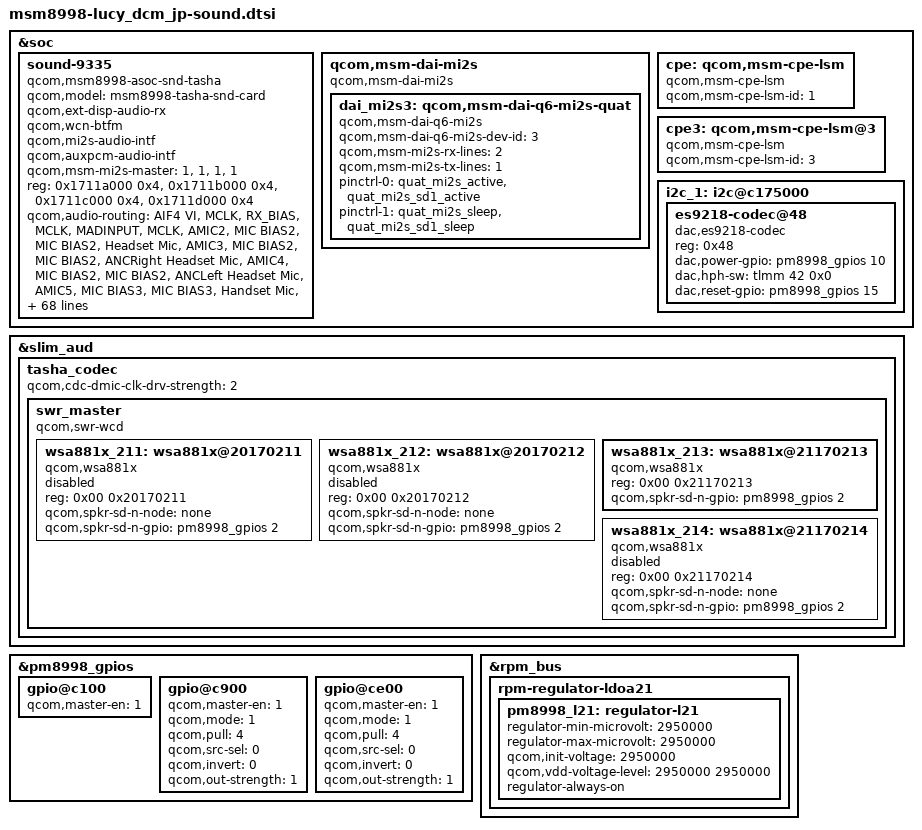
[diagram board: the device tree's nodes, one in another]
/* Copyright (c) 2016, The Linux Foundation. All rights reserved.
 *
 * This program is free software; you can redistribute it and/or modify
 * it under the terms of the GNU General Public License version 2 and
 * only version 2 as published by the Free Software Foundation.
 *
 * This program is distributed in the hope that it will be useful,
 * but WITHOUT ANY WARRANTY; without even the implied warranty of
 * MERCHANTABILITY or FITNESS FOR A PARTICULAR PURPOSE.  See the
 * GNU General Public License for more details.
 */

&soc {
	/delete-node/ sound-tavil;
	/delete-node/ msm_cdc_pinctrl@75;
	/delete-node/ qcom,wcd-dsp-mgr;

	sound-9335 {
		compatible = "qcom,msm8998-asoc-snd-tasha";
		qcom,model = "msm8998-tasha-snd-card";
		qcom,ext-disp-audio-rx;
		qcom,wcn-btfm;
		qcom,mi2s-audio-intf;
		qcom,auxpcm-audio-intf;
		qcom,msm-mi2s-master = <1>, <1>, <1>, <1>;

		reg = <0x1711a000 0x4>,
		      <0x1711b000 0x4>,
		      <0x1711c000 0x4>,
		      <0x1711d000 0x4>;
		reg-names = "lpaif_pri_mode_muxsel",
			    "lpaif_sec_mode_muxsel",
			    "lpaif_tert_mode_muxsel",
			    "lpaif_quat_mode_muxsel";

		qcom,audio-routing =
			"AIF4 VI", "MCLK",
			"RX_BIAS", "MCLK",
			"MADINPUT", "MCLK",
			"AMIC2", "MIC BIAS2",
			"MIC BIAS2", "Headset Mic",
			"AMIC3", "MIC BIAS2",
			"MIC BIAS2", "ANCRight Headset Mic",
			"AMIC4", "MIC BIAS2",
			"MIC BIAS2", "ANCLeft Headset Mic",
			"AMIC5", "MIC BIAS3",
			"MIC BIAS3", "Handset Mic",
			"AMIC6", "MIC BIAS4",
			"MIC BIAS4", "Analog Mic6",
			"DMIC0", "MIC BIAS1",
			"MIC BIAS1", "Digital Mic0",
			"DMIC1", "MIC BIAS1",
			"MIC BIAS1", "Digital Mic1",
			"DMIC2", "MIC BIAS3",
			"MIC BIAS3", "Digital Mic2",
			"DMIC3", "MIC BIAS3",
			"MIC BIAS3", "Digital Mic3",
			"DMIC4", "MIC BIAS4",
			"MIC BIAS4", "Digital Mic4",
			"DMIC5", "MIC BIAS4",
			"MIC BIAS4", "Digital Mic5",
			"SpkrLeft IN", "SPK1 OUT";

		qcom,msm-mbhc-hphl-swh = <1>;
		qcom,msm-mbhc-gnd-swh = <0>;
		qcom,mbhc-audio-jack-type = "4-pole-jack";
		/delete-property/ qcom,us-euro-gpios;
		lge,msm-mbhc-extn-cable = <0>;

		qcom,tasha-mclk-clk-freq = <9600000>;
		asoc-platform = <&pcm0>, <&pcm1>, <&pcm2>, <&voip>, <&voice>,
				<&loopback>, <&compress>, <&hostless>,
				<&afe>, <&lsm>, <&routing>, <&cpe>, <&compr>,
				<&pcm_noirq>, <&cpe3>;
		asoc-platform-names = "msm-pcm-dsp.0", "msm-pcm-dsp.1",
				"msm-pcm-dsp.2", "msm-voip-dsp",
				"msm-pcm-voice", "msm-pcm-loopback",
				"msm-compress-dsp", "msm-pcm-hostless",
				"msm-pcm-afe", "msm-lsm-client",
				"msm-pcm-routing", "msm-cpe-lsm",
				"msm-compr-dsp", "msm-pcm-dsp-noirq",
				"msm-cpe-lsm.3";
		asoc-cpu = <&dai_hdmi>, <&dai_dp>,
				<&dai_mi2s0>, <&dai_mi2s1>,
				<&dai_mi2s2>, <&dai_mi2s3>,
				<&dai_pri_auxpcm>, <&dai_sec_auxpcm>,
				<&dai_tert_auxpcm>, <&dai_quat_auxpcm>,
				<&sb_0_rx>, <&sb_0_tx>, <&sb_1_rx>, <&sb_1_tx>,
				<&sb_2_rx>, <&sb_2_tx>, <&sb_3_rx>, <&sb_3_tx>,
				<&sb_4_rx>, <&sb_4_tx>, <&sb_5_tx>,
				<&afe_pcm_rx>, <&afe_pcm_tx>, <&afe_proxy_rx>,
				<&afe_proxy_tx>, <&incall_record_rx>,
				<&incall_record_tx>, <&incall_music_rx>,
				<&incall_music_2_rx>, <&sb_5_rx>, <&sb_6_rx>,
				<&sb_7_rx>, <&sb_7_tx>, <&sb_8_tx>,
				<&usb_audio_rx>, <&usb_audio_tx>,
				<&dai_pri_tdm_rx_0>, <&dai_pri_tdm_tx_0>,
				<&dai_sec_tdm_rx_0>, <&dai_sec_tdm_tx_0>,
				<&dai_tert_tdm_rx_0>, <&dai_tert_tdm_tx_0>,
				<&dai_quat_tdm_rx_0>, <&dai_quat_tdm_tx_0>;
		asoc-cpu-names = "msm-dai-q6-hdmi.8", "msm-dai-q6-dp.24608",
				"msm-dai-q6-mi2s.0", "msm-dai-q6-mi2s.1",
				"msm-dai-q6-mi2s.2", "msm-dai-q6-mi2s.3",
				"msm-dai-q6-auxpcm.1", "msm-dai-q6-auxpcm.2",
				"msm-dai-q6-auxpcm.3", "msm-dai-q6-auxpcm.4",
				"msm-dai-q6-dev.16384", "msm-dai-q6-dev.16385",
				"msm-dai-q6-dev.16386", "msm-dai-q6-dev.16387",
				"msm-dai-q6-dev.16388", "msm-dai-q6-dev.16389",
				"msm-dai-q6-dev.16390", "msm-dai-q6-dev.16391",
				"msm-dai-q6-dev.16392", "msm-dai-q6-dev.16393",
				"msm-dai-q6-dev.16395", "msm-dai-q6-dev.224",
				"msm-dai-q6-dev.225", "msm-dai-q6-dev.241",
				"msm-dai-q6-dev.240", "msm-dai-q6-dev.32771",
				"msm-dai-q6-dev.32772", "msm-dai-q6-dev.32773",
				"msm-dai-q6-dev.32770", "msm-dai-q6-dev.16394",
				"msm-dai-q6-dev.16396", "msm-dai-q6-dev.16398",
				"msm-dai-q6-dev.16399", "msm-dai-q6-dev.16401",
				"msm-dai-q6-dev.28672", "msm-dai-q6-dev.28673",
				"msm-dai-q6-tdm.36864", "msm-dai-q6-tdm.36865",
				"msm-dai-q6-tdm.36880", "msm-dai-q6-tdm.36881",
				"msm-dai-q6-tdm.36896", "msm-dai-q6-tdm.36897",
				"msm-dai-q6-tdm.36912", "msm-dai-q6-tdm.36913";
		asoc-codec = <&stub_codec>, <&ext_disp_audio_codec>;
		asoc-codec-names = "msm-stub-codec.1",
				   "msm-ext-disp-audio-codec-rx";
		qcom,wsa-max-devs = <1>;
		qcom,wsa-devs = <&wsa881x_213>;
		qcom,wsa-aux-dev-prefix = "SpkrLeft";
		qcom,wcn-btfm;
	};

	qcom,msm-dai-mi2s {
		compatible = "qcom,msm-dai-mi2s";
		dai_mi2s3: qcom,msm-dai-q6-mi2s-quat {
			compatible = "qcom,msm-dai-q6-mi2s";
			qcom,msm-dai-q6-mi2s-dev-id = <3>;
			qcom,msm-mi2s-rx-lines = <2>; /* SD1 used as output */
			qcom,msm-mi2s-tx-lines = <1>; /* SD0 used as input */
			pinctrl-names = "default", "idle";
			pinctrl-0 = <&quat_mi2s_active &quat_mi2s_sd1_active>;
			pinctrl-1 = <&quat_mi2s_sleep &quat_mi2s_sd1_sleep>;
		};
	};

	cpe: qcom,msm-cpe-lsm {
		compatible = "qcom,msm-cpe-lsm";
		qcom,msm-cpe-lsm-id = <1>;
	};

	cpe3: qcom,msm-cpe-lsm@3 {
		compatible = "qcom,msm-cpe-lsm";
		qcom,msm-cpe-lsm-id = <3>;
	};

	i2c_1: i2c@c175000 { /* BLSP1 QUP1 */
		status = "okay";

		es9218-codec@48 {
			compatible = "dac,es9218-codec";
			status = "ok";
			reg = <0x48>;
			dac,power-gpio = <&pm8998_gpios 10 0x0>;
			dac,hph-sw = <&tlmm 42 0x0>;
			dac,reset-gpio = <&pm8998_gpios 15 0x0>;
		};
	};

};

&slim_aud {
	/delete-node/ tavil_codec;

	tasha_codec {
		qcom,cdc-dmic-clk-drv-strength = <2>;
		swr_master {
			compatible = "qcom,swr-wcd";
			#address-cells = <2>;
			#size-cells = <0>;
			wsa881x_211: wsa881x@20170211 {
				compatible = "qcom,wsa881x";
				reg = <0x00 0x20170211>;
				qcom,spkr-sd-n-node = "none";
				qcom,spkr-sd-n-gpio = <&pm8998_gpios 2 0>;
				status = "disabled";
			};
			wsa881x_212: wsa881x@20170212 {
				compatible = "qcom,wsa881x";
				reg = <0x00 0x20170212>;
				qcom,spkr-sd-n-node = "none";
				qcom,spkr-sd-n-gpio = <&pm8998_gpios 2 0>;
				status = "disabled";
			};
			wsa881x_213: wsa881x@21170213 {
				compatible = "qcom,wsa881x";
				reg = <0x00 0x21170213>;
				/delete-property/ qcom,spkr-sd-n-node;
				qcom,spkr-sd-n-gpio = <&pm8998_gpios 2 0>;
				status = "ok";
			};
			wsa881x_214: wsa881x@21170214 {
				compatible = "qcom,wsa881x";
				reg = <0x00 0x21170214>;
				qcom,spkr-sd-n-node = "none";
				qcom,spkr-sd-n-gpio = <&pm8998_gpios 2 0>;
				status = "disabled";
			};
		};
	};
};


&pm8998_gpios {
	/* qcom,spkr-sd-n-gpio */
        gpio@c100 {
                qcom,master-en = <1>;   /* ENABLE GPIO */
                status = "okay";
        };

        /* dac,power-gpio */
        gpio@c900 {
                qcom,master-en = <1>;   	/* ENABLE GPIO */
                qcom,mode = <1>;		/* Digital output */
                qcom,pull = <4>;		/* Pull down */
                qcom,src-sel = <0>;		/* Constant */
                qcom,invert = <0>;		/* Invert */
                qcom,out-strength = <1>;	/* Low */
                status = "okay";
        };

        /* dac,reset-gpio */
        gpio@ce00 {
		qcom,master-en = <1>;		/* Enable GPIO */
		qcom,mode = <1>;		/* Digital output */
                qcom,pull = <4>;		/* Pull down */
                qcom,src-sel = <0>;		/* Constant */
                qcom,invert = <0>;		/* Invert */
                qcom,out-strength = <1>;	/* Low */
                status = "okay";
        };
};

&rpm_bus {
    rpm-regulator-ldoa21 {
        status = "okay";
        pm8998_l21: regulator-l21 {
            regulator-min-microvolt = <2950000>;
            regulator-max-microvolt = <2950000>;
            qcom,init-voltage = <2950000>;
            qcom,vdd-voltage-level = <2950000 2950000>;
            regulator-always-on;
            status = "okay";
        };
    };
};
